AUTOSAR XML (schema 4-2-2)
package /Components
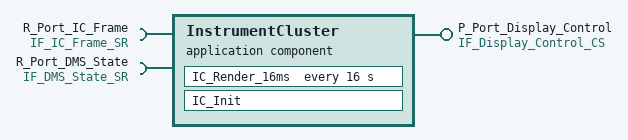
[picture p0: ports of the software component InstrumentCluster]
  application sw component type InstrumentCluster
    provide port P_Port_Display_Control: provided-interface=IF_Display_Control_CS
    require port R_Port_IC_Frame: required-interface=IF_IC_Frame_SR
    require port R_Port_DMS_State: required-interface=IF_DMS_State_SR
    behavior InstrumentCluster_InternalBehavior
      data received event IC_Frame_Received: start-on-event=IC_Render_16ms
      init event IC_Init_Event: start-on-event=IC_Init
      timing event IC_Render_Tick: start-on-event=IC_Render_16ms, period=16
      runnable IC_Init
        data-read-access:
          access VA_Init_Read_DMS_Timestamp: accessed-variable=R_Port_DMS_State.Timestamp
        data-receive-point-by-arguments:
          access VA_Init_Read_Theme_Id: accessed-variable=R_Port_IC_Frame.Theme_Id
        parameter access PA_Init_Read_UI_Theme: accessed-parameter=R_Port_IC_Frame.Theme_Id
        parameter access PA_Init_Read_Timestamp: accessed-parameter=R_Port_IC_Frame.Timestamp
      runnable IC_Render_16ms: minimum-start-interval=16
        data-read-access:
          4 x access:
            VA_Read_DMS_Attention: accessed-variable=R_Port_DMS_State.Driver_Attention
            VA_Read_DMS_Drowsiness: accessed-variable=R_Port_DMS_State.Drowsiness_Level
            VA_Read_DMS_EyesOffRoad: accessed-variable=R_Port_DMS_State.Eyes_Off_Road
            VA_Read_DMS_Timestamp: accessed-variable=R_Port_DMS_State.Timestamp
        data-receive-point-by-arguments:
          access VA_Receive_IC_Frame: accessed-variable=R_Port_IC_Frame.IC_Frame
          access VA_Receive_IC_Theme: accessed-variable=R_Port_IC_Frame.Theme_Id
          access VA_Receive_IC_Timestamp: accessed-variable=R_Port_IC_Frame.Timestamp
        parameter access PA_Render_Read_Params: accessed-parameter=R_Port_DMS_State.Timestamp
